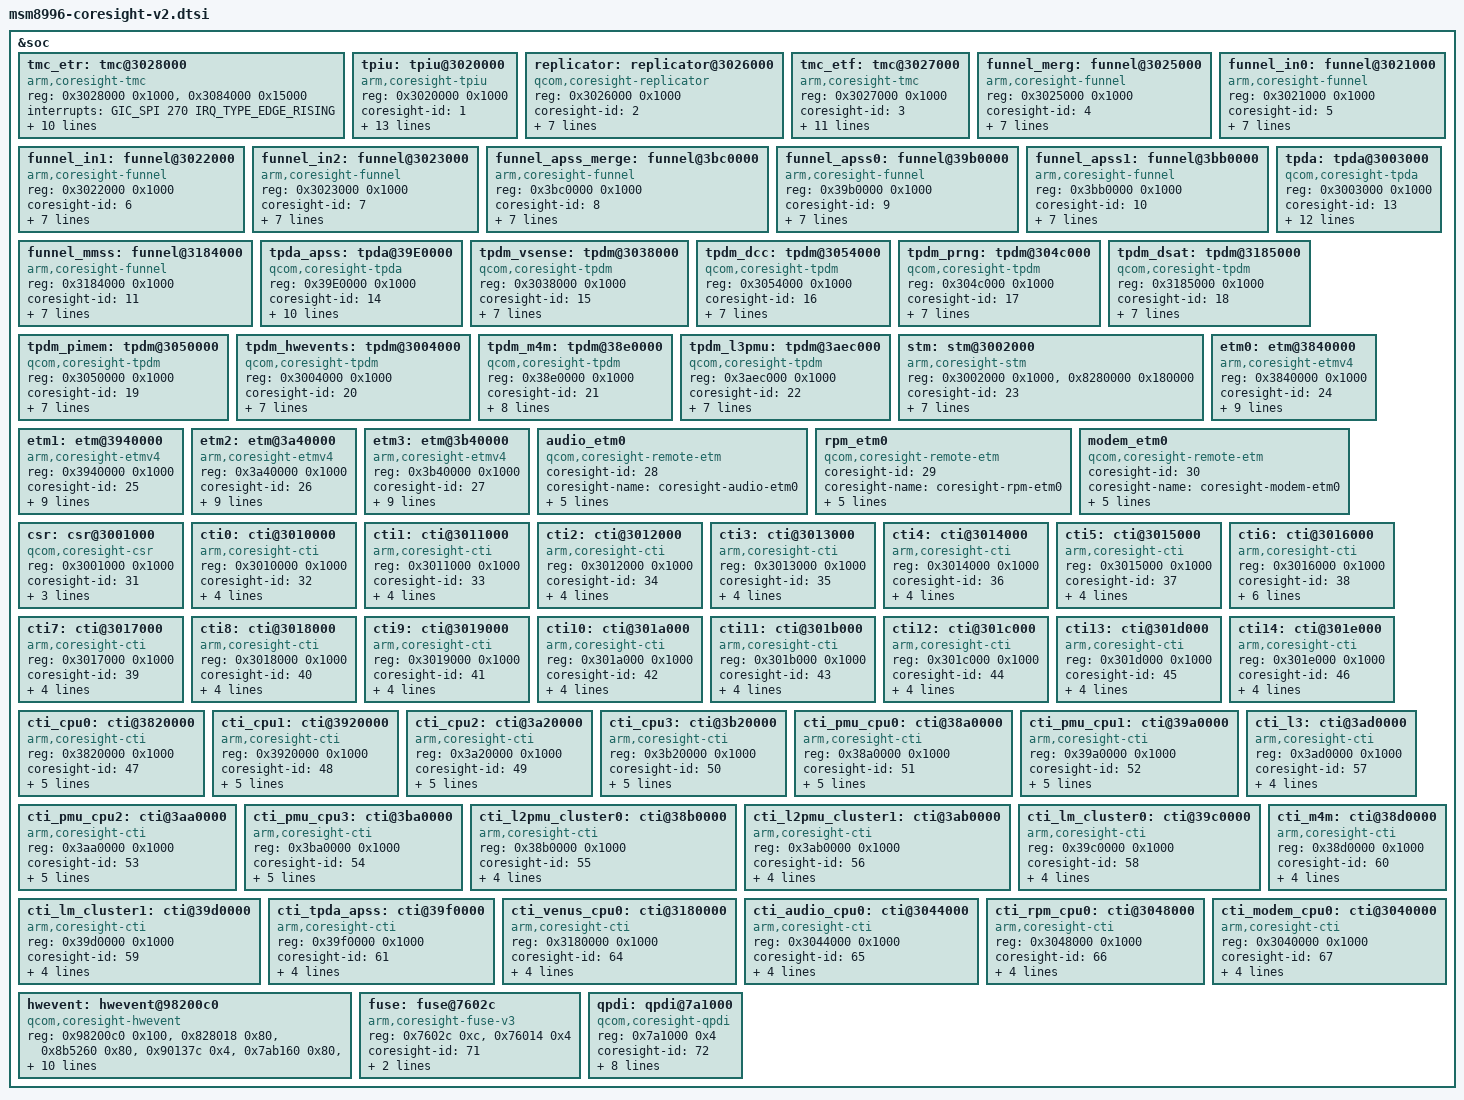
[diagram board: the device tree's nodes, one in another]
/* Copyright (c) 2015, The Linux Foundation. All rights reserved.
 *
 * This program is free software; you can redistribute it and/or modify
 * it under the terms of the GNU General Public License version 2 and
 * only version 2 as published by the Free Software Foundation.
 *
 * This program is distributed in the hope that it will be useful,
 * but WITHOUT ANY WARRANTY; without even the implied warranty of
 * MERCHANTABILITY or FITNESS FOR A PARTICULAR PURPOSE.  See the
 * GNU General Public License for more details.
 */

#include <dt-bindings/interrupt-controller/arm-gic.h>

&soc {
	tmc_etr: tmc@3028000 {
		compatible = "arm,coresight-tmc";
		reg = <0x3028000 0x1000>,
		      <0x3084000 0x15000>;
		reg-names = "tmc-base", "bam-base";
		interrupts = <GIC_SPI 270 IRQ_TYPE_EDGE_RISING>;
		interrupt-names = "byte-cntr-irq";

		qcom,memory-size = <0x400000>;
		qcom,tmc-flush-powerdown;
		qcom,sg-enable;
		qcom,force-reg-dump;

		coresight-id = <0>;
		coresight-name = "coresight-tmc-etr";
		coresight-nr-inports = <1>;
		coresight-ctis = <&cti0 &cti8>;

		clocks = <&clock_gcc clk_qdss_clk>,
			 <&clock_gcc clk_qdss_a_clk>;
		clock-names = "core_clk", "core_a_clk";
	};

	tpiu: tpiu@3020000 {
		compatible = "arm,coresight-tpiu";
		reg = <0x3020000 0x1000>;
		reg-names = "tpiu-base";

		coresight-id = <1>;
		coresight-name = "coresight-tpiu";
		coresight-nr-inports = <1>;

		vdd-supply = <&pm8994_l21>;
		qcom,vdd-voltage-level = <2950000 2950000>;
		qcom,vdd-current-level = <200 800000>;

		vdd-io-supply = <&pm8994_l13>;
		qcom,vdd-io-voltage-level = <2950000 2950000>;
		qcom,vdd-io-current-level = <200 22000>;

		qcom,nidntsw;
		qcom,nidnt-swduart;
		qcom,nidnt-swdtrc;

		clocks = <&clock_gcc clk_qdss_clk>,
			 <&clock_gcc clk_qdss_a_clk>;
		clock-names = "core_clk", "core_a_clk";
	};

	replicator: replicator@3026000 {
		compatible = "qcom,coresight-replicator";
		reg = <0x3026000 0x1000>;
		reg-names = "replicator-base";

		coresight-id = <2>;
		coresight-name = "coresight-replicator";
		coresight-nr-inports = <1>;
		coresight-outports = <0 1>;
		coresight-child-list = <&tmc_etr &tpiu>;
		coresight-child-ports = <0 0>;

		clocks = <&clock_gcc clk_qdss_clk>,
			 <&clock_gcc clk_qdss_a_clk>;
		clock-names = "core_clk", "core_a_clk";
	};

	tmc_etf: tmc@3027000 {
		compatible = "arm,coresight-tmc";
		reg = <0x3027000 0x1000>;
		reg-names = "tmc-base";

		coresight-id = <3>;
		coresight-name = "coresight-tmc-etf";
		coresight-nr-inports = <1>;
		coresight-outports = <0>;
		coresight-child-list = <&replicator>;
		coresight-child-ports = <0>;
		coresight-default-sink;
		coresight-ctis = <&cti0 &cti8>;

		qcom,tmc-flush-powerdown;
		qcom,force-reg-dump;

		clocks = <&clock_gcc clk_qdss_clk>,
			 <&clock_gcc clk_qdss_a_clk>;
		clock-names = "core_clk", "core_a_clk";
	};

	funnel_merg: funnel@3025000 {
		compatible = "arm,coresight-funnel";
		reg = <0x3025000 0x1000>;
		reg-names = "funnel-base";

		coresight-id = <4>;
		coresight-name = "coresight-funnel-merg";
		coresight-nr-inports = <2>;
		coresight-outports = <0>;
		coresight-child-list = <&tmc_etf>;
		coresight-child-ports = <0>;

		clocks = <&clock_gcc clk_qdss_clk>,
			 <&clock_gcc clk_qdss_a_clk>;
		clock-names = "core_clk", "core_a_clk";
	};

	funnel_in0: funnel@3021000 {
		compatible = "arm,coresight-funnel";
		reg = <0x3021000 0x1000>;
		reg-names = "funnel-base";

		coresight-id = <5>;
		coresight-name = "coresight-funnel-in0";
		coresight-nr-inports = <8>;
		coresight-outports = <0>;
		coresight-child-list = <&funnel_merg>;
		coresight-child-ports = <0>;

		clocks = <&clock_gcc clk_qdss_clk>,
			 <&clock_gcc clk_qdss_a_clk>;
		clock-names = "core_clk", "core_a_clk";
	};

	funnel_in1: funnel@3022000 {
		compatible = "arm,coresight-funnel";
		reg = <0x3022000 0x1000>;
		reg-names = "funnel-base";

		coresight-id = <6>;
		coresight-name = "coresight-funnel-in1";
		coresight-nr-inports = <8>;
		coresight-outports = <0>;
		coresight-child-list = <&funnel_merg>;
		coresight-child-ports = <1>;

		clocks = <&clock_gcc clk_qdss_clk>,
			 <&clock_gcc clk_qdss_a_clk>;
		clock-names = "core_clk", "core_a_clk";
	};

	funnel_in2: funnel@3023000 {
		compatible = "arm,coresight-funnel";
		reg = <0x3023000 0x1000>;
		reg-names = "funnel-base";

		coresight-id = <7>;
		coresight-name = "coresight-funnel-in2";
		coresight-nr-inports = <8>;
		coresight-outports = <0>;
		coresight-child-list = <&funnel_merg>;
		coresight-child-ports = <2>;

		clocks = <&clock_gcc clk_qdss_clk>,
			 <&clock_gcc clk_qdss_a_clk>;
		clock-names = "core_clk", "core_a_clk";
	};

	funnel_apss_merge: funnel@3bc0000 {
		compatible = "arm,coresight-funnel";
		reg = <0x3bc0000 0x1000>;
		reg-names = "funnel-base";

		coresight-id = <8>;
		coresight-name = "coresight-funnel-apss-merge";
		coresight-nr-inports = <4>;
		coresight-outports = <0>;
		coresight-child-list = <&funnel_in1>;
		coresight-child-ports = <6>;

		clocks = <&clock_gcc clk_qdss_clk>,
			 <&clock_gcc clk_qdss_a_clk>;
		clock-names = "core_clk", "core_a_clk";
	};

	funnel_apss0: funnel@39b0000 {
		compatible = "arm,coresight-funnel";
		reg = <0x39b0000 0x1000>;
		reg-names = "funnel-base";

		coresight-id = <9>;
		coresight-name = "coresight-funnel-apss0";
		coresight-nr-inports = <2>;
		coresight-outports = <0>;
		coresight-child-list = <&funnel_apss_merge>;
		coresight-child-ports = <0>;

		clocks = <&clock_gcc clk_qdss_clk>,
			 <&clock_gcc clk_qdss_a_clk>;
		clock-names = "core_clk", "core_a_clk";
	};

	funnel_apss1: funnel@3bb0000 {
		compatible = "arm,coresight-funnel";
		reg = <0x3bb0000 0x1000>;
		reg-names = "funnel-base";

		coresight-id = <10>;
		coresight-name = "coresight-funnel-apss1";
		coresight-nr-inports = <2>;
		coresight-outports = <0>;
		coresight-child-list = <&funnel_apss_merge>;
		coresight-child-ports = <1>;

		clocks = <&clock_gcc clk_qdss_clk>,
			 <&clock_gcc clk_qdss_a_clk>;
		clock-names = "core_clk", "core_a_clk";
	};

	funnel_mmss: funnel@3184000 {
		compatible = "arm,coresight-funnel";
		reg = <0x3184000 0x1000>;
		reg-names = "funnel-base";

		coresight-id = <11>;
		coresight-name = "coresight-funnel-mmss";
		coresight-nr-inports = <8>;
		coresight-outports = <0>;
		coresight-child-list = <&funnel_in0>;
		coresight-child-ports = <1>;

		clocks = <&clock_gcc clk_qdss_clk>,
			 <&clock_gcc clk_qdss_a_clk>;
		clock-names = "core_clk", "core_a_clk";
	};

	tpda: tpda@3003000 {
		compatible = "qcom,coresight-tpda";
		reg = <0x3003000 0x1000>;
		reg-names = "tpda-base";

		coresight-id = <13>;
		coresight-name = "coresight-tpda";
		coresight-nr-inports = <32>;
		coresight-outports = <0>;
		coresight-child-list = <&funnel_in0>;
		coresight-child-ports = <3>;

		qcom,tpda-atid = <65>;
		qcom,bc-elem-size = <3 32>,
				    <6 32>;
		qcom,tc-elem-size = <3 32>,
				    <6 32>;
		qcom,dsb-elem-size = <3 32>,
				     <6 32>,
				     <7 32>;
		qcom,cmb-elem-size = <0 32>,
				     <1 32>,
				     <2 32>,
				     <6 64>;

		clocks = <&clock_gcc clk_qdss_clk>,
			 <&clock_gcc clk_qdss_a_clk>;
		clock-names = "core_clk", "core_a_clk";
	};

	tpda_apss: tpda@39E0000 {
		compatible = "qcom,coresight-tpda";
		reg = <0x39E0000 0x1000>;
		reg-names = "tpda-base";

		coresight-id = <14>;
		coresight-name = "coresight-tpda-apss";
		coresight-nr-inports = <32>;
		coresight-outports = <0>;
		coresight-child-list = <&funnel_apss_merge>;
		coresight-child-ports = <2>;

		qcom,tpda-atid = <66>;
		qcom,bc-elem-size = <0 32>,
				    <1 32>;
		qcom,tc-elem-size = <0 32>;

		clocks = <&clock_gcc clk_qdss_clk>,
			 <&clock_gcc clk_qdss_a_clk>;
		clock-names = "core_clk", "core_a_clk";
	};

	tpdm_vsense: tpdm@3038000 {
		compatible = "qcom,coresight-tpdm";
		reg = <0x3038000 0x1000>;
		reg-names = "tpdm-base";

		coresight-id = <15>;
		coresight-name = "coresight-tpdm-vsense";
		coresight-nr-inports = <0>;
		coresight-outports = <0>;
		coresight-child-list = <&tpda>;
		coresight-child-ports = <0>;

		clocks = <&clock_gcc clk_qdss_clk>,
			 <&clock_gcc clk_qdss_a_clk>;
		clock-names = "core_clk", "core_a_clk";
	};

	tpdm_dcc: tpdm@3054000 {
		compatible = "qcom,coresight-tpdm";
		reg = <0x3054000 0x1000>;
		reg-names = "tpdm-base";

		coresight-id = <16>;
		coresight-name = "coresight-tpdm-dcc";
		coresight-nr-inports = <0>;
		coresight-outports = <0>;
		coresight-child-list = <&tpda>;
		coresight-child-ports = <1>;

		clocks = <&clock_gcc clk_qdss_clk>,
			 <&clock_gcc clk_qdss_a_clk>;
		clock-names = "core_clk", "core_a_clk";
	};

	tpdm_prng: tpdm@304c000 {
		compatible = "qcom,coresight-tpdm";
		reg = <0x304c000 0x1000>;
		reg-names = "tpdm-base";

		coresight-id = <17>;
		coresight-name = "coresight-tpdm-prng";
		coresight-nr-inports = <0>;
		coresight-outports = <0>;
		coresight-child-list = <&tpda>;
		coresight-child-ports = <2>;

		clocks = <&clock_gcc clk_qdss_clk>,
			 <&clock_gcc clk_qdss_a_clk>;
		clock-names = "core_clk", "core_a_clk";
	};

	tpdm_dsat: tpdm@3185000 {
		compatible = "qcom,coresight-tpdm";
		reg = <0x3185000 0x1000>;
		reg-names = "tpdm-base";

		coresight-id = <18>;
		coresight-name = "coresight-tpdm-dsat";
		coresight-nr-inports = <0>;
		coresight-outports = <0>;
		coresight-child-list = <&tpda>;
		coresight-child-ports = <3>;

		clocks = <&clock_gcc clk_qdss_clk>,
			 <&clock_gcc clk_qdss_a_clk>;
		clock-names = "core_clk", "core_a_clk";
	};

	tpdm_pimem: tpdm@3050000 {
		compatible = "qcom,coresight-tpdm";
		reg = <0x3050000 0x1000>;
		reg-names = "tpdm-base";

		coresight-id = <19>;
		coresight-name = "coresight-tpdm-pimem";
		coresight-nr-inports = <0>;
		coresight-outports = <0>;
		coresight-child-list = <&tpda>;
		coresight-child-ports = <6>;

		clocks = <&clock_gcc clk_qdss_clk>,
			 <&clock_gcc clk_qdss_a_clk>;
		clock-names = "core_clk", "core_a_clk";
	};

	tpdm_hwevents: tpdm@3004000 {
		compatible = "qcom,coresight-tpdm";
		reg = <0x3004000 0x1000>;
		reg-names = "tpdm-base";

		coresight-id = <20>;
		coresight-name = "coresight-tpdm-hwevents";
		coresight-nr-inports = <0>;
		coresight-outports = <0>;
		coresight-child-list = <&tpda>;
		coresight-child-ports = <7>;

		clocks = <&clock_gcc clk_qdss_clk>,
			 <&clock_gcc clk_qdss_a_clk>;
		clock-names = "core_clk", "core_a_clk";
	};

	tpdm_m4m: tpdm@38e0000 {
		compatible = "qcom,coresight-tpdm";
		reg = <0x38e0000 0x1000>;
		reg-names = "tpdm-base";

		coresight-id = <21>;
		coresight-name = "coresight-tpdm-m4m";
		coresight-nr-inports = <0>;
		coresight-outports = <0>;
		coresight-child-list = <&tpda_apss>;
		coresight-child-ports = <0>;

		qcom,clk-enable;

		clocks = <&clock_gcc clk_qdss_clk>,
			 <&clock_gcc clk_qdss_a_clk>;
		clock-names = "core_clk", "core_a_clk";
	};

	tpdm_l3pmu: tpdm@3aec000 {
		compatible = "qcom,coresight-tpdm";
		reg = <0x3aec000 0x1000>;
		reg-names = "tpdm-base";

		coresight-id = <22>;
		coresight-name = "coresight-tpdm-l3pmu";
		coresight-nr-inports = <0>;
		coresight-outports = <0>;
		coresight-child-list = <&tpda_apss>;
		coresight-child-ports = <1>;

		clocks = <&clock_gcc clk_qdss_clk>,
			 <&clock_gcc clk_qdss_a_clk>;
		clock-names = "core_clk", "core_a_clk";
	};

	stm: stm@3002000 {
		compatible = "arm,coresight-stm";
		reg = <0x3002000 0x1000>,
		      <0x8280000 0x180000>;
		reg-names = "stm-base", "stm-data-base";

		coresight-id = <23>;
		coresight-name = "coresight-stm";
		coresight-nr-inports = <0>;
		coresight-outports = <0>;
		coresight-child-list = <&funnel_in0>;
		coresight-child-ports = <7>;

		clocks = <&clock_gcc clk_qdss_clk>,
			 <&clock_gcc clk_qdss_a_clk>;
		clock-names = "core_clk", "core_a_clk";
	};

	etm0: etm@3840000 {
		compatible = "arm,coresight-etmv4";
		reg = <0x3840000 0x1000>;
		reg-names = "etm-base";

		coresight-id = <24>;
		coresight-name = "coresight-etm0";
		coresight-nr-inports = <0>;
		coresight-outports = <0>;
		coresight-child-list = <&funnel_apss0>;
		coresight-child-ports = <0>;
		coresight-etm-cpu = <&CPU0>;

		qcom,noovrflw-enable;

		clocks = <&clock_gcc clk_qdss_clk>,
			 <&clock_gcc clk_qdss_a_clk>;
		clock-names = "core_clk", "core_a_clk";
	};

	etm1: etm@3940000 {
		compatible = "arm,coresight-etmv4";
		reg = <0x3940000 0x1000>;
		reg-names = "etm-base";

		coresight-id = <25>;
		coresight-name = "coresight-etm1";
		coresight-nr-inports = <0>;
		coresight-outports = <0>;
		coresight-child-list = <&funnel_apss0>;
		coresight-child-ports = <1>;
		coresight-etm-cpu = <&CPU1>;

		qcom,noovrflw-enable;

		clocks = <&clock_gcc clk_qdss_clk>,
			 <&clock_gcc clk_qdss_a_clk>;
		clock-names = "core_clk", "core_a_clk";
	};

	etm2: etm@3a40000 {
		compatible = "arm,coresight-etmv4";
		reg = <0x3a40000 0x1000>;
		reg-names = "etm-base";

		coresight-id = <26>;
		coresight-name = "coresight-etm2";
		coresight-nr-inports = <0>;
		coresight-outports = <0>;
		coresight-child-list = <&funnel_apss1>;
		coresight-child-ports = <0>;
		coresight-etm-cpu = <&CPU2>;

		qcom,noovrflw-enable;

		clocks = <&clock_gcc clk_qdss_clk>,
			 <&clock_gcc clk_qdss_a_clk>;
		clock-names = "core_clk", "core_a_clk";
	};

	etm3: etm@3b40000 {
		compatible = "arm,coresight-etmv4";
		reg = <0x3b40000 0x1000>;
		reg-names = "etm-base";

		coresight-id = <27>;
		coresight-name = "coresight-etm3";
		coresight-nr-inports = <0>;
		coresight-outports = <0>;
		coresight-child-list = <&funnel_apss1>;
		coresight-child-ports = <1>;
		coresight-etm-cpu = <&CPU3>;

		qcom,noovrflw-enable;

		clocks = <&clock_gcc clk_qdss_clk>,
			 <&clock_gcc clk_qdss_a_clk>;
		clock-names = "core_clk", "core_a_clk";
	};

	audio_etm0 {
		compatible = "qcom,coresight-remote-etm";

		coresight-id = <28>;
		coresight-name = "coresight-audio-etm0";
		coresight-nr-inports = <0>;
		coresight-outports = <0>;
		coresight-child-list = <&funnel_in0>;
		coresight-child-ports = <2>;

		qcom,inst-id = <5>;
	};

	rpm_etm0 {
		compatible = "qcom,coresight-remote-etm";

		coresight-id = <29>;
		coresight-name = "coresight-rpm-etm0";
		coresight-nr-inports = <0>;
		coresight-outports = <0>;
		coresight-child-list = <&funnel_in0>;
		coresight-child-ports = <0>;

		qcom,inst-id = <4>;
	};

	modem_etm0 {
		compatible = "qcom,coresight-remote-etm";

		coresight-id = <30>;
		coresight-name = "coresight-modem-etm0";
		coresight-nr-inports = <0>;
		coresight-outports = <0>;
		coresight-child-list = <&funnel_in2>;
		coresight-child-ports = <0>;

		qcom,inst-id = <2>;
	};

	csr: csr@3001000 {
		compatible = "qcom,coresight-csr";
		reg = <0x3001000 0x1000>;
		reg-names = "csr-base";

		coresight-id = <31>;
		coresight-name = "coresight-csr";
		coresight-nr-inports = <0>;

		qcom,blk-size = <1>;
	};

	cti0: cti@3010000 {
		compatible = "arm,coresight-cti";
		reg = <0x3010000 0x1000>;
		reg-names = "cti-base";

		coresight-id = <32>;
		coresight-name = "coresight-cti0";
		coresight-nr-inports = <0>;

		clocks = <&clock_gcc clk_qdss_clk>,
			 <&clock_gcc clk_qdss_a_clk>;
		clock-names = "core_clk", "core_a_clk";
	};

	cti1: cti@3011000 {
		compatible = "arm,coresight-cti";
		reg = <0x3011000 0x1000>;
		reg-names = "cti-base";

		coresight-id = <33>;
		coresight-name = "coresight-cti1";
		coresight-nr-inports = <0>;

		clocks = <&clock_gcc clk_qdss_clk>,
			 <&clock_gcc clk_qdss_a_clk>;
		clock-names = "core_clk", "core_a_clk";
	};

	cti2: cti@3012000 {
		compatible = "arm,coresight-cti";
		reg = <0x3012000 0x1000>;
		reg-names = "cti-base";

		coresight-id = <34>;
		coresight-name = "coresight-cti2";
		coresight-nr-inports = <0>;

		clocks = <&clock_gcc clk_qdss_clk>,
			 <&clock_gcc clk_qdss_a_clk>;
		clock-names = "core_clk", "core_a_clk";
	};

	cti3: cti@3013000 {
		compatible = "arm,coresight-cti";
		reg = <0x3013000 0x1000>;
		reg-names = "cti-base";

		coresight-id = <35>;
		coresight-name = "coresight-cti3";
		coresight-nr-inports = <0>;

		clocks = <&clock_gcc clk_qdss_clk>,
			 <&clock_gcc clk_qdss_a_clk>;
		clock-names = "core_clk", "core_a_clk";
	};

	cti4: cti@3014000 {
		compatible = "arm,coresight-cti";
		reg = <0x3014000 0x1000>;
		reg-names = "cti-base";

		coresight-id = <36>;
		coresight-name = "coresight-cti4";
		coresight-nr-inports = <0>;

		clocks = <&clock_gcc clk_qdss_clk>,
			 <&clock_gcc clk_qdss_a_clk>;
		clock-names = "core_clk", "core_a_clk";
	};

	cti5: cti@3015000 {
		compatible = "arm,coresight-cti";
		reg = <0x3015000 0x1000>;
		reg-names = "cti-base";

		coresight-id = <37>;
		coresight-name = "coresight-cti5";
		coresight-nr-inports = <0>;

		clocks = <&clock_gcc clk_qdss_clk>,
			 <&clock_gcc clk_qdss_a_clk>;
		clock-names = "core_clk", "core_a_clk";
	};

	cti6: cti@3016000 {
		compatible = "arm,coresight-cti";
		reg = <0x3016000 0x1000>;
		reg-names = "cti-base";

		coresight-id = <38>;
		coresight-name = "coresight-cti6";
		coresight-nr-inports = <0>;

		clocks = <&clock_gcc clk_qdss_clk>,
			 <&clock_gcc clk_qdss_a_clk>;
		clock-names = "core_clk", "core_a_clk";

		qcom,cti-gpio-trigout = <2>;
		pinctrl-names = "cti-trigout-pctrl";
		pinctrl-0 = <&trigout_a>;
	};

	cti7: cti@3017000 {
		compatible = "arm,coresight-cti";
		reg = <0x3017000 0x1000>;
		reg-names = "cti-base";

		coresight-id = <39>;
		coresight-name = "coresight-cti7";
		coresight-nr-inports = <0>;

		clocks = <&clock_gcc clk_qdss_clk>,
			 <&clock_gcc clk_qdss_a_clk>;
		clock-names = "core_clk", "core_a_clk";
	};

	cti8: cti@3018000 {
		compatible = "arm,coresight-cti";
		reg = <0x3018000 0x1000>;
		reg-names = "cti-base";

		coresight-id = <40>;
		coresight-name = "coresight-cti8";
		coresight-nr-inports = <0>;

		clocks = <&clock_gcc clk_qdss_clk>,
			 <&clock_gcc clk_qdss_a_clk>;
		clock-names = "core_clk", "core_a_clk";
	};

	cti9: cti@3019000 {
		compatible = "arm,coresight-cti";
		reg = <0x3019000 0x1000>;
		reg-names = "cti-base";

		coresight-id = <41>;
		coresight-name = "coresight-cti9";
		coresight-nr-inports = <0>;

		clocks = <&clock_gcc clk_qdss_clk>,
			 <&clock_gcc clk_qdss_a_clk>;
		clock-names = "core_clk", "core_a_clk";
	};

	cti10: cti@301a000 {
		compatible = "arm,coresight-cti";
		reg = <0x301a000 0x1000>;
		reg-names = "cti-base";

		coresight-id = <42>;
		coresight-name = "coresight-cti10";
		coresight-nr-inports = <0>;

		clocks = <&clock_gcc clk_qdss_clk>,
			 <&clock_gcc clk_qdss_a_clk>;
		clock-names = "core_clk", "core_a_clk";
	};

	cti11: cti@301b000 {
		compatible = "arm,coresight-cti";
		reg = <0x301b000 0x1000>;
		reg-names = "cti-base";

		coresight-id = <43>;
		coresight-name = "coresight-cti11";
		coresight-nr-inports = <0>;

		clocks = <&clock_gcc clk_qdss_clk>,
			 <&clock_gcc clk_qdss_a_clk>;
		clock-names = "core_clk", "core_a_clk";
	};

	cti12: cti@301c000 {
		compatible = "arm,coresight-cti";
		reg = <0x301c000 0x1000>;
		reg-names = "cti-base";

		coresight-id = <44>;
		coresight-name = "coresight-cti12";
		coresight-nr-inports = <0>;

		clocks = <&clock_gcc clk_qdss_clk>,
			 <&clock_gcc clk_qdss_a_clk>;
		clock-names = "core_clk", "core_a_clk";
	};

	cti13: cti@301d000 {
		compatible = "arm,coresight-cti";
		reg = <0x301d000 0x1000>;
		reg-names = "cti-base";

		coresight-id = <45>;
		coresight-name = "coresight-cti13";
		coresight-nr-inports = <0>;

		clocks = <&clock_gcc clk_qdss_clk>,
			 <&clock_gcc clk_qdss_a_clk>;
		clock-names = "core_clk", "core_a_clk";
	};

	cti14: cti@301e000 {
		compatible = "arm,coresight-cti";
		reg = <0x301e000 0x1000>;
		reg-names = "cti-base";

		coresight-id = <46>;
		coresight-name = "coresight-cti14";
		coresight-nr-inports = <0>;

		clocks = <&clock_gcc clk_qdss_clk>,
			 <&clock_gcc clk_qdss_a_clk>;
		clock-names = "core_clk", "core_a_clk";
	};

	cti_cpu0: cti@3820000 {
		compatible = "arm,coresight-cti";
		reg = <0x3820000 0x1000>;
		reg-names = "cti-base";

		coresight-id = <47>;
		coresight-name = "coresight-cti-cpu0";
		coresight-nr-inports = <0>;
		coresight-cti-cpu = <&CPU0>;

		clocks = <&clock_gcc clk_qdss_clk>,
			 <&clock_gcc clk_qdss_a_clk>;
		clock-names = "core_clk", "core_a_clk";
	};

	cti_cpu1: cti@3920000 {
		compatible = "arm,coresight-cti";
		reg = <0x3920000 0x1000>;
		reg-names = "cti-base";

		coresight-id = <48>;
		coresight-name = "coresight-cti-cpu1";
		coresight-nr-inports = <0>;
		coresight-cti-cpu = <&CPU1>;

		clocks = <&clock_gcc clk_qdss_clk>,
			 <&clock_gcc clk_qdss_a_clk>;
		clock-names = "core_clk", "core_a_clk";
	};

	cti_cpu2: cti@3a20000 {
		compatible = "arm,coresight-cti";
		reg = <0x3a20000 0x1000>;
		reg-names = "cti-base";

		coresight-id = <49>;
		coresight-name = "coresight-cti-cpu2";
		coresight-nr-inports = <0>;
		coresight-cti-cpu = <&CPU2>;

		clocks = <&clock_gcc clk_qdss_clk>,
			 <&clock_gcc clk_qdss_a_clk>;
		clock-names = "core_clk", "core_a_clk";
	};

	cti_cpu3: cti@3b20000 {
		compatible = "arm,coresight-cti";
		reg = <0x3b20000 0x1000>;
		reg-names = "cti-base";

		coresight-id = <50>;
		coresight-name = "coresight-cti-cpu3";
		coresight-nr-inports = <0>;
		coresight-cti-cpu = <&CPU3>;

		clocks = <&clock_gcc clk_qdss_clk>,
			 <&clock_gcc clk_qdss_a_clk>;
		clock-names = "core_clk", "core_a_clk";
	};

	cti_pmu_cpu0: cti@38a0000 {
		compatible = "arm,coresight-cti";
		reg = <0x38a0000 0x1000>;
		reg-names = "cti-base";

		coresight-id = <51>;
		coresight-name = "coresight-cti-pmu-cpu0";
		coresight-nr-inports = <0>;
		coresight-cti-cpu = <&CPU0>;

		clocks = <&clock_gcc clk_qdss_clk>,
			 <&clock_gcc clk_qdss_a_clk>;
		clock-names = "core_clk", "core_a_clk";
	};

	cti_pmu_cpu1: cti@39a0000 {
		compatible = "arm,coresight-cti";
		reg = <0x39a0000 0x1000>;
		reg-names = "cti-base";

		coresight-id = <52>;
		coresight-name = "coresight-cti-pmu-cpu1";
		coresight-nr-inports = <0>;
		coresight-cti-cpu = <&CPU1>;

		clocks = <&clock_gcc clk_qdss_clk>,
			 <&clock_gcc clk_qdss_a_clk>;
		clock-names = "core_clk", "core_a_clk";
	};

	cti_pmu_cpu2: cti@3aa0000 {
		compatible = "arm,coresight-cti";
		reg = <0x3aa0000 0x1000>;
		reg-names = "cti-base";

		coresight-id = <53>;
		coresight-name = "coresight-cti-pmu-cpu2";
		coresight-nr-inports = <0>;
		coresight-cti-cpu = <&CPU2>;

		clocks = <&clock_gcc clk_qdss_clk>,
			 <&clock_gcc clk_qdss_a_clk>;
		clock-names = "core_clk", "core_a_clk";
	};

	cti_pmu_cpu3: cti@3ba0000 {
		compatible = "arm,coresight-cti";
		reg = <0x3ba0000 0x1000>;
		reg-names = "cti-base";

		coresight-id = <54>;
		coresight-name = "coresight-cti-pmu-cpu3";
		coresight-nr-inports = <0>;
		coresight-cti-cpu = <&CPU3>;

		clocks = <&clock_gcc clk_qdss_clk>,
			 <&clock_gcc clk_qdss_a_clk>;
		clock-names = "core_clk", "core_a_clk";
	};

	cti_l2pmu_cluster0: cti@38b0000 {
		compatible = "arm,coresight-cti";
		reg = <0x38b0000 0x1000>;
		reg-names = "cti-base";

		coresight-id = <55>;
		coresight-name = "coresight-cti-l2pmu-cluster0";
		coresight-nr-inports = <0>;

		clocks = <&clock_gcc clk_qdss_clk>,
			 <&clock_gcc clk_qdss_a_clk>;
		clock-names = "core_clk", "core_a_clk";
	};

	cti_l2pmu_cluster1: cti@3ab0000 {
		compatible = "arm,coresight-cti";
		reg = <0x3ab0000 0x1000>;
		reg-names = "cti-base";

		coresight-id = <56>;
		coresight-name = "coresight-cti-l2pmu-cluster1";
		coresight-nr-inports = <0>;

		clocks = <&clock_gcc clk_qdss_clk>,
			 <&clock_gcc clk_qdss_a_clk>;
		clock-names = "core_clk", "core_a_clk";
	};

	cti_l3: cti@3ad0000 {
		compatible = "arm,coresight-cti";
		reg = <0x3ad0000 0x1000>;
		reg-names = "cti-base";

		coresight-id = <57>;
		coresight-name = "coresight-cti-l3";
		coresight-nr-inports = <0>;

		clocks = <&clock_gcc clk_qdss_clk>,
			 <&clock_gcc clk_qdss_a_clk>;
		clock-names = "core_clk", "core_a_clk";
	};

	cti_lm_cluster0: cti@39c0000 {
		compatible = "arm,coresight-cti";
		reg = <0x39c0000 0x1000>;
		reg-names = "cti-base";

		coresight-id = <58>;
		coresight-name = "coresight-cti-lm-cluster0";
		coresight-nr-inports = <0>;

		clocks = <&clock_gcc clk_qdss_clk>,
			 <&clock_gcc clk_qdss_a_clk>;
		clock-names = "core_clk", "core_a_clk";
	};

	cti_lm_cluster1: cti@39d0000 {
		compatible = "arm,coresight-cti";
		reg = <0x39d0000 0x1000>;
		reg-names = "cti-base";

		coresight-id = <59>;
		coresight-name = "coresight-cti-lm-cluster1";
		coresight-nr-inports = <0>;

		clocks = <&clock_gcc clk_qdss_clk>,
			 <&clock_gcc clk_qdss_a_clk>;
		clock-names = "core_clk", "core_a_clk";
	};

	cti_m4m: cti@38d0000 {
		compatible = "arm,coresight-cti";
		reg = <0x38d0000 0x1000>;
		reg-names = "cti-base";

		coresight-id = <60>;
		coresight-name = "coresight-cti-m4m";
		coresight-nr-inports = <0>;

		clocks = <&clock_gcc clk_qdss_clk>,
			 <&clock_gcc clk_qdss_a_clk>;
		clock-names = "core_clk", "core_a_clk";
	};

	cti_tpda_apss: cti@39f0000 {
		compatible = "arm,coresight-cti";
		reg = <0x39f0000 0x1000>;
		reg-names = "cti-base";

		coresight-id = <61>;
		coresight-name = "coresight-cti-tpda-apss";
		coresight-nr-inports = <0>;

		clocks = <&clock_gcc clk_qdss_clk>,
			 <&clock_gcc clk_qdss_a_clk>;
		clock-names = "core_clk", "core_a_clk";
	};

	cti_venus_cpu0: cti@3180000 {
		compatible = "arm,coresight-cti";
		reg = <0x3180000 0x1000>;
		reg-names = "cti-base";

		coresight-id = <64>;
		coresight-name = "coresight-cti-venus-cpu0";
		coresight-nr-inports = <0>;

		clocks = <&clock_gcc clk_qdss_clk>,
			 <&clock_gcc clk_qdss_a_clk>;
		clock-names = "core_clk", "core_a_clk";
	};

	cti_audio_cpu0: cti@3044000 {
		compatible = "arm,coresight-cti";
		reg = <0x3044000 0x1000>;
		reg-names = "cti-base";

		coresight-id = <65>;
		coresight-name = "coresight-cti-audio-cpu0";
		coresight-nr-inports = <0>;

		clocks = <&clock_gcc clk_qdss_clk>,
			 <&clock_gcc clk_qdss_a_clk>;
		clock-names = "core_clk", "core_a_clk";
	};

	cti_rpm_cpu0: cti@3048000 {
		compatible = "arm,coresight-cti";
		reg = <0x3048000 0x1000>;
		reg-names = "cti-base";

		coresight-id = <66>;
		coresight-name = "coresight-cti-rpm-cpu0";
		coresight-nr-inports = <0>;

		clocks = <&clock_gcc clk_qdss_clk>,
			 <&clock_gcc clk_qdss_a_clk>;
		clock-names = "core_clk", "core_a_clk";
	};

	cti_modem_cpu0: cti@3040000 {
		compatible = "arm,coresight-cti";
		reg = <0x3040000 0x1000>;
		reg-names = "cti-base";

		coresight-id = <67>;
		coresight-name = "coresight-cti-modem-cpu0";
		coresight-nr-inports = <0>;

		clocks = <&clock_gcc clk_qdss_clk>,
			 <&clock_gcc clk_qdss_a_clk>;
		clock-names = "core_clk", "core_a_clk";
	};

	hwevent: hwevent@98200c0 {
		compatible = "qcom,coresight-hwevent";
		reg = <0x98200c0 0x100>,
		      <0x828018 0x80>,
		      <0x8b5260 0x80>,
		      <0x90137c 0x4>,
		      <0x7ab160 0x80>,
		      <0x358000 0x40>,
		      <0x359000 0x40>,
		      <0x600058 0x80>,
		      <0x608058 0x80>,
		      <0x610058 0x80>,
		      <0x7ab360 0x80>,
		      <0x7ab760 0x80>,
		      <0x7abf60 0x80>;
		reg-names = "hmss-mux", "mmss-mux", "dsa-stm", "mdss-mdp",
			    "phss-hwev", "gcc-eve1", "gcc-eve2", "pcie0-hwev",
			    "pcie1-hwev", "pcie2-hwev", "tcsr-mux", "mss-mux0",
			    "mss-mux1";

		coresight-id = <70>;
		coresight-name = "coresight-hwevent";
		coresight-nr-inports = <0>;

		clocks = <&clock_gcc clk_qdss_clk>,
			 <&clock_gcc clk_qdss_a_clk>,
			 <&clock_mmss clk_mmss_misc_ahb_clk>;
		clock-names = "core_clk", "core_a_clk", "core_mmss_clk";

		qcom,hwevent-clks = "core_mmss_clk";
	};

	fuse: fuse@7602c {
		compatible = "arm,coresight-fuse-v3";
		reg = <0x7602c 0xc>,
		      <0x76014 0x4>;
		reg-names = "fuse-base", "qpdi-fuse-base";

		coresight-id = <71>;
		coresight-name = "coresight-fuse";
		coresight-nr-inports = <0>;
	};

	qpdi: qpdi@7a1000 {
		compatible = "qcom,coresight-qpdi";
		reg = <0x7a1000 0x4>;
		reg-names = "qpdi-base";

		coresight-id = <72>;
		coresight-name = "coresight-qpdi";
		coresight-nr-inports = <0>;

		vdd-supply = <&pm8994_l21>;
		qcom,vdd-voltage-level = <2950000 2950000>;
		qcom,vdd-current-level = <200 800000>;

		vdd-io-supply = <&pm8994_l13>;
		qcom,vdd-io-voltage-level = <2950000 2950000>;
		qcom,vdd-io-current-level = <200 22000>;
	};
};
